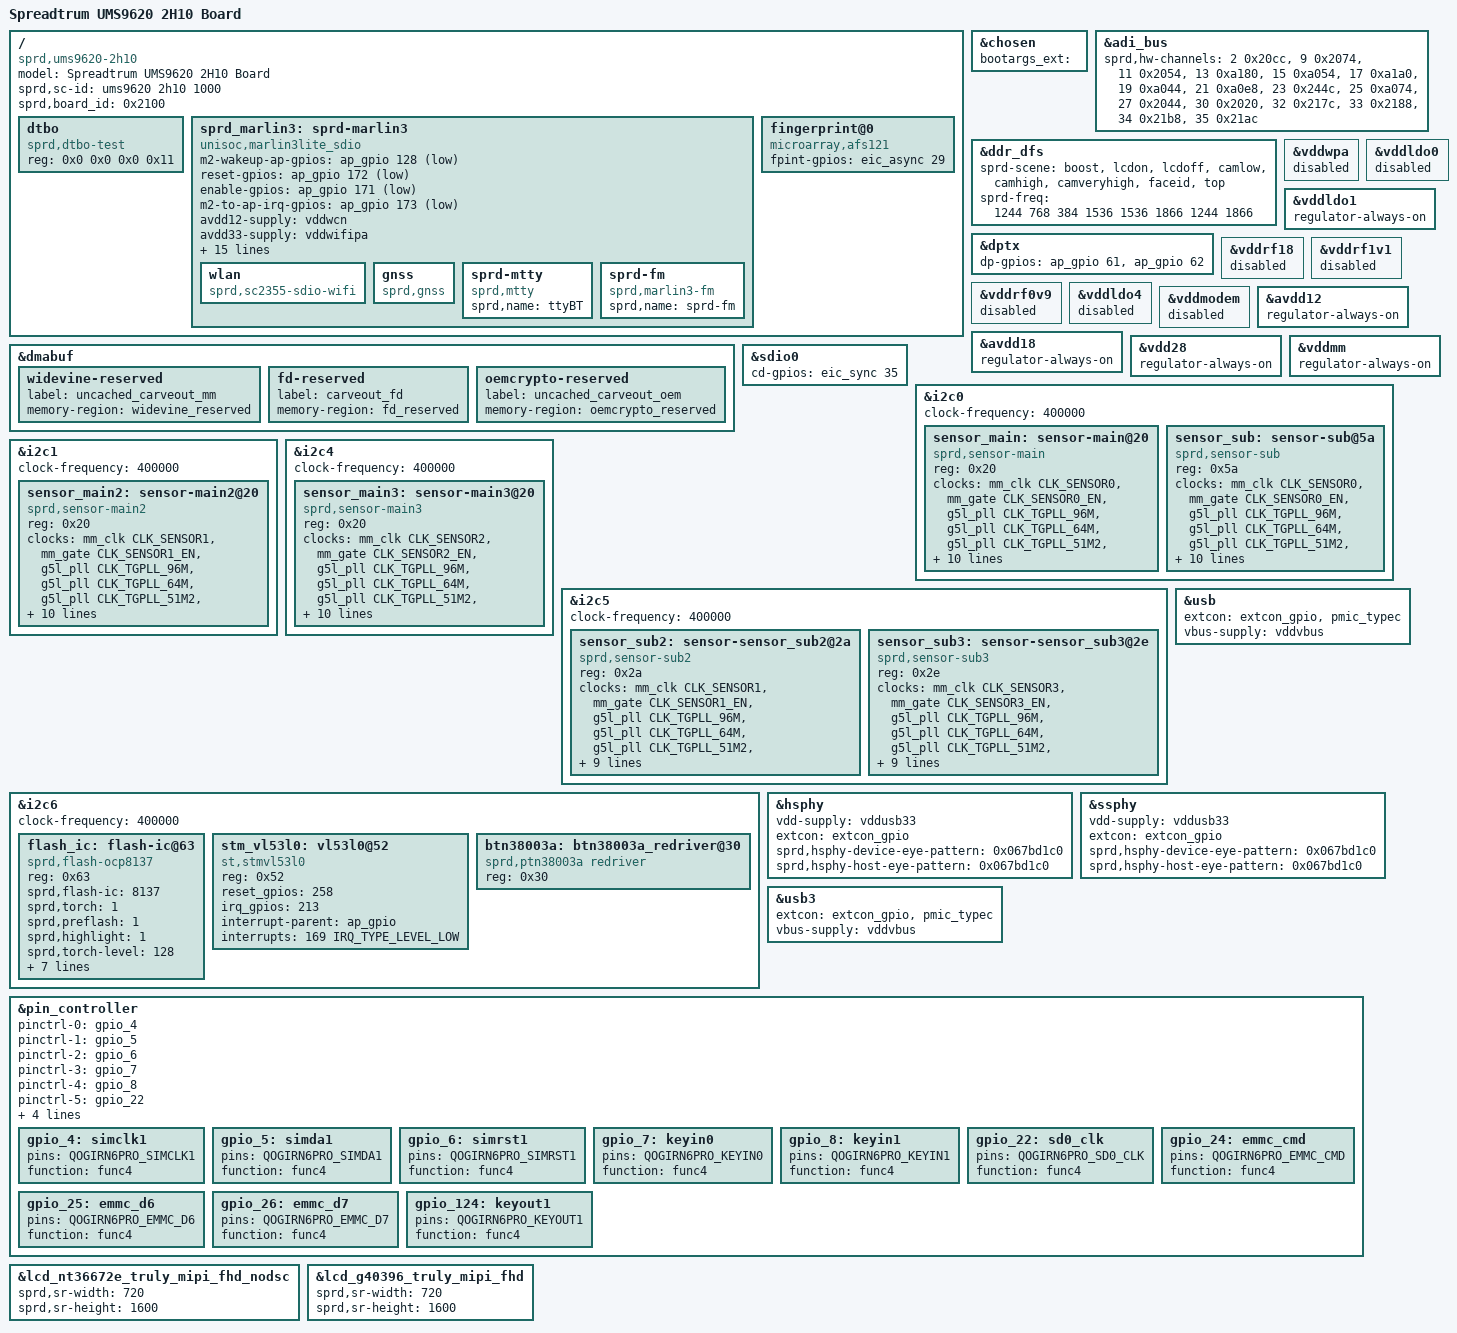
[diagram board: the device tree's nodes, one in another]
/dts-v1/;
/plugin/;
#include <dt-bindings/gpio/gpio.h>
#include <dt-bindings/interrupt-controller/arm-gic.h>
#include <dt-bindings/clock/sprd,ums9620-clk.h>
#include <dt-bindings/usb/pd.h>
#include "lcd/lcd_g40396_truly_mipi_fhd.dtsi"
#include "lcd/lcd_nt36672e_truly_mipi_fhd_nodsc.dtsi"
#include "lcd/lcd_dummy_mipi.dtsi"
#include "reserved-memory/ums9620-2h10-overlay.dtsi"
#include "touchscreen/ums9620-spi1-gpio13-14-tp.dtsi"
#include "battery/ums9620-2h10-overlay.dtsi"
#include <dt-bindings/mfd/sprd,ump9620-regs.h>
#include <dt-bindings/mfd/sprd,ump9620-mask.h>
#include <dt-bindings/input/input.h>
#include <dt-bindings/clock/sprd,ums9620-clk.h>

/ {

	model = "Spreadtrum UMS9620 2H10 Board";

	compatible = "sprd,ums9620-2h10", "sprd,ums9620";

	sprd,sc-id = "ums9620 2h10 1000";

	sprd,board_id = <0x2100>; //XX00:base board,XX00~XXFF:customize board

	fragment {
		target-path = "/";
		__overlay__ {
			#address-cells = <2>;
			#size-cells = <2>;

			dtbo: dtbo {
				compatible = "sprd,dtbo-test";
				reg = <0x0 0x0 0x0 0x11>;
			};
			sprd_marlin3: sprd-marlin3 {
				compatible = "unisoc,marlin3lite_sdio";
				m2-wakeup-ap-gpios = <&ap_gpio 128 GPIO_ACTIVE_LOW>;
				reset-gpios = <&ap_gpio 172 GPIO_ACTIVE_LOW>;
				enable-gpios = <&ap_gpio 171 GPIO_ACTIVE_LOW>;
				m2-to-ap-irq-gpios = <&ap_gpio 173 GPIO_ACTIVE_LOW>;
				/* xtal-26m-clk-type = "TCXO"; */
				avdd12-supply = <&vddwcn>;
				avdd33-supply = <&vddwifipa>;
				dcxo18-supply = <&vddsim2>;
				clock-names = "clk_32k","source","enable";
				clocks = <&aonapb_gate CLK_AUX0>,
					 <&ext_32k>,
					 <&aonapb_gate CLK_AUX0_EB>;
				extcon = <&sdio1>;
				sdhci-name = <&sdio1>;
				sprd,btwf-file-name = "/dev/block/by-name/wcnmodem";
				sprd,gnss-file-name = "/vendor/firmware/gnssmodem.bin";
				adma-tx;
				adma-rx;
				/*
				 * bound parameter:
				 * [0]:addr offset, [1]:mask, [2]:unboundval, [3]:boundval
				 */
				avdd12-bound-wbreq = <REG_ANA_LDO_XTL_EN10 MASK_ANA_LDO_VDDWCN_EXT_XTL3_EN 0x0 MASK_ANA_LDO_VDDWCN_EXT_XTL3_EN>;
				avdd33-bound-wbreq = <REG_ANA_LDO_XTL_EN11 MASK_ANA_LDO_VDDWIFIPA_EXT_XTL3_EN 0x0 MASK_ANA_LDO_VDDWIFIPA_EXT_XTL3_EN>;

				wlan {
					compatible = "sprd,sc2355-sdio-wifi";
				};

				gnss {
					compatible = "sprd,gnss";
				};

				sprd-mtty {
					compatible = "sprd,mtty";
					sprd,name = "ttyBT";
				};

				sprd-fm {
					compatible = "sprd,marlin3-fm";
					sprd,name = "sprd-fm";
				};

			};

			fingerprint@0 {
				compatible = "microarray,afs121";
				fpint-gpios = <&eic_async 29 0>;
  			};

		};
	};
};

&chosen {
	bootargs_ext = "";
};

&adi_bus {
	sprd,hw-channels = <2 0x20cc>, <9 0x2074>, <11 0x2054>, <13 0xa180>,
			<15 0xa054>, <17 0xa1a0>, <19 0xa044>, <21 0xa0e8>,
			<23 0x244c>, <25 0xa074>, <27 0x2044>, <30 0x2020>,
			<32 0x217c>, <33 0x2188>, <34 0x21b8>, <35 0x21ac>;
};

&ddr_dfs {
		sprd-scene = "boost", "lcdon", "lcdoff", "camlow",
			"camhigh", "camveryhigh", "faceid", "top";
		sprd-freq = <1244 768 384 1536 1536 1866 1244 1866>;
};

&dptx {
	dp-gpios = <&ap_gpio 61 GPIO_ACTIVE_HIGH>,
			<&ap_gpio 62 GPIO_ACTIVE_HIGH>;
};

&vddwpa {
	status = "disabled";
};

&vddldo0 {
	status = "disabled";
};

&vddldo1 {
	regulator-always-on;
};

&vddrf18 {
	status = "disabled";
};

&vddrf1v1 {
	status = "disabled";
};

&vddrf0v9 {
	status = "disabled";
};

&vddldo4 {
	status = "disabled";
};

&vddmodem {
	status = "disabled";
};

&avdd12 {
	regulator-always-on;
};

&avdd18 {
	regulator-always-on;
};

&vdd28 {
	regulator-always-on;
};

&vddmm {
	regulator-always-on;
};

&dmabuf {
	widevine-reserved {
		label = "uncached_carveout_mm";
		memory-region = <&widevine_reserved>;
	};

	fd-reserved {
		label = "carveout_fd";
		memory-region = <&fd_reserved>;
	};

	oemcrypto-reserved {
		label = "uncached_carveout_oem";
		memory-region = <&oemcrypto_reserved>;
	};
};

&sdio0 {
	cd-gpios = <&eic_sync 35 GPIO_ACTIVE_HIGH>;
};

&i2c0 {
	status = "okay";
	clock-frequency = <400000>;

	sensor_main: sensor-main@20 {
		compatible = "sprd,sensor-main";
		reg = <0x20>;
		clock-names = "clk_src","sensor_eb",
			"clk_96m","clk_64m",
			"clk_51m2","clk_48m","clk_26m";
		clocks = <&mm_clk CLK_SENSOR0>,<&mm_gate CLK_SENSOR0_EN>,
				<&g5l_pll CLK_TGPLL_96M>,<&g5l_pll CLK_TGPLL_64M>,
				<&g5l_pll CLK_TGPLL_51M2>,<&g5l_pll CLK_TGPLL_48M>,<&ext_26m>;
		vddio-supply = <&vddcamio>;
		vddcama-supply = <&vddcama0>;
		vddcamd-supply = <&vddcamd0>;
		vddcammot-supply = <&vddcammot0>;
		reset-gpios = <&ap_gpio 40 0>;
		power-down-gpios = <&ap_gpio 46 0>;
		sprd,phyid = <0>;
		csi = <&csi0>;
		power-domains = <&mm_domain>;
	};

	sensor_sub: sensor-sub@5a {
		compatible = "sprd,sensor-sub";
		reg = <0x5a>;
		clock-names = "clk_src","sensor_eb",
			"clk_96m","clk_64m",
			"clk_51m2","clk_48m","clk_26m";
		clocks = <&mm_clk CLK_SENSOR0>,<&mm_gate CLK_SENSOR0_EN>,
			<&g5l_pll CLK_TGPLL_96M>,<&g5l_pll CLK_TGPLL_64M>,
			<&g5l_pll CLK_TGPLL_51M2>,<&g5l_pll CLK_TGPLL_48M>,<&ext_26m>;
		vddio-supply = <&vddcamio>;
		vddcama-supply = <&vddcama0>;
		vddcamd-supply = <&vddcamd0>;
		vddcammot-supply = <&vddcammot0>;
		reset-gpios = <&ap_gpio 39 0>;
		power-down-gpios = <&ap_gpio 45 0>;
		sprd,phyid = <1>;
		csi = <&csi1>;
		power-domains = <&mm_domain>;
	};
};

&i2c1 {
	status = "okay";
	clock-frequency = <400000>;

	sensor_main2: sensor-main2@20 {
		compatible = "sprd,sensor-main2";
		reg = <0x20>;
		clock-names = "clk_src","sensor_eb",
			"clk_96m","clk_64m",
			"clk_51m2","clk_48m","clk_26m";
		clocks = <&mm_clk CLK_SENSOR1>,<&mm_gate CLK_SENSOR1_EN>,
			<&g5l_pll CLK_TGPLL_96M>,<&g5l_pll CLK_TGPLL_64M>,
			<&g5l_pll CLK_TGPLL_51M2>,<&g5l_pll CLK_TGPLL_48M>,<&ext_26m>;
		vddio-supply = <&vddcamio>;
		vddcama-supply = <&vddcama1>;
		avdd-gpios = <&ap_gpio 79 0>;
		vddcamd-supply = <&vddcamd1>;
		reset-gpios = <&ap_gpio 41 0>;
		power-down-gpios = <&ap_gpio 47 0>;
		sprd,phyid = <3>;/*6*/
		csi = <&csi3>;
		power-domains = <&mm_domain>;
	};
};

&i2c4 {
	status = "okay";
	clock-frequency = <400000>;

	sensor_main3: sensor-main3@20 {
		compatible = "sprd,sensor-main3";
		reg = <0x20>;
		clock-names = "clk_src","sensor_eb",
			"clk_96m","clk_64m",
			"clk_51m2","clk_48m","clk_26m";
		clocks = <&mm_clk CLK_SENSOR2>,<&mm_gate CLK_SENSOR2_EN>,
			<&g5l_pll CLK_TGPLL_96M>,<&g5l_pll CLK_TGPLL_64M>,
			<&g5l_pll CLK_TGPLL_51M2>,<&g5l_pll CLK_TGPLL_48M>,<&ext_26m>;
		vddio-supply = <&vddcamio>;
		vddcama-supply = <&vddcama2>;
		vddcamd-supply = <&vddcamd2>;
		vddcammot-supply = <&vddcammot1>;
		mot-gpios = <&ap_gpio 78 0>;
		reset-gpios = <&ap_gpio 42 0>;
		sprd,phyid = <2>;/*4*/
		csi = <&csi2>;
		power-domains = <&mm_domain>;
	};
};

&i2c5 {
	status = "okay";
	clock-frequency = <400000>;

	sensor_sub2: sensor-sensor_sub2@2a {
		compatible = "sprd,sensor-sub2";
		reg = <0x2a>;
		clock-names = "clk_src","sensor_eb",
			"clk_96m","clk_64m",
			"clk_51m2","clk_48m","clk_26m";
		clocks = <&mm_clk CLK_SENSOR1>,<&mm_gate CLK_SENSOR1_EN>,
			<&g5l_pll CLK_TGPLL_96M>,<&g5l_pll CLK_TGPLL_64M>,
			<&g5l_pll CLK_TGPLL_51M2>,<&g5l_pll CLK_TGPLL_48M>,<&ext_26m>;
		vddio-supply = <&vddcamio>;
		vddcama-supply = <&vddcama1>;
		vddcamd-supply = <&vddcamd1>;
		reset-gpios = <&ap_gpio 44 0>;
		power-down-gpios = <&ap_gpio 50 0>;
		sprd,phyid = <5>;
		csi = <&csi2>;
		power-domains = <&mm_domain>;
	};

	sensor_sub3: sensor-sensor_sub3@2e {
		compatible = "sprd,sensor-sub3";
		reg = <0x2e>;
		clock-names = "clk_src","sensor_eb",
			"clk_96m","clk_64m",
			"clk_51m2","clk_48m","clk_26m";
		clocks = <&mm_clk CLK_SENSOR3>,<&mm_gate CLK_SENSOR3_EN>,
			<&g5l_pll CLK_TGPLL_96M>,<&g5l_pll CLK_TGPLL_64M>,
			<&g5l_pll CLK_TGPLL_51M2>,<&g5l_pll CLK_TGPLL_48M>,<&ext_26m>;
		vddio-supply = <&vddcamio>;
		vddcama-supply = <&vddcama2>;
		vddcamd-supply = <&vddcamd2>;
		reset-gpios = <&ap_gpio 43 0>;
		power-down-gpios = <&ap_gpio 49 0>;
		sprd,phyid = <7>;
		csi = <&csi3>;
		power-domains = <&mm_domain>;
	};
};

&i2c6 {
	status = "okay";
	clock-frequency = <400000>;

	flash_ic: flash-ic@63 {
		compatible = "sprd,flash-ocp8137";
		reg = <0x63>;
		sprd,flash-ic = <8137>;
		sprd,torch = <1>;
		sprd,preflash = <1>;
		sprd,highlight = <1>;
		sprd,torch-level = <128>;
		sprd,preflash-level = <128>;
		sprd,highlight-level = <128>;
		sprd,lvfm-enable = <1>;
		flash-torch-en-gpios = <&ap_gpio 112 0>;
		flash-chip-en-gpios = <&ap_gpio 119 0>;
		flash-en-gpios = <&ap_gpio 111 0>;
		flash-sync-gpios = <&ap_gpio 59 0>;
	};

	stm_vl53l0: vl53l0@52 {
		compatible = "st,stmvl53l0";
		reg = <0x52>;
		reset_gpios = <258>;
		irq_gpios = <213>;
		interrupt-parent = <&ap_gpio>;
		interrupts = <169 IRQ_TYPE_LEVEL_LOW>;
	};

	btn38003a: btn38003a_redriver@30 {
		compatible = "sprd,ptn38003a redriver";
		reg = <0x30>;
	};
};

&hsphy {
	vdd-supply = <&vddusb33>;
	extcon = <&extcon_gpio>;
	sprd,hsphy-device-eye-pattern = <0x067bd1c0>;
	sprd,hsphy-host-eye-pattern = <0x067bd1c0>;
	status = "okay";
};

&usb {
	extcon = <&extcon_gpio>, <&pmic_typec>;
	vbus-supply = <&vddvbus>;
	status = "okay";
};

&ssphy {
	vdd-supply = <&vddusb33>;
	extcon = <&extcon_gpio>;
	sprd,hsphy-device-eye-pattern = <0x067bd1c0>;
	sprd,hsphy-host-eye-pattern = <0x067bd1c0>;
	status = "okay";
};

&usb3 {
	extcon = <&extcon_gpio>, <&pmic_typec>;
	vbus-supply = <&vddvbus>;
	status = "okay";
};

&pin_controller {
	pinctrl-names =
	/* IM1_CLK ,SIM1_DA ,SIM1_RST ,keyin0 */
	 "gpio_4", "gpio_5", "gpio_6", "gpio_7",
	/* keyin1 ,sd0_clk, emmc_cmd */
	"gpio_8", "gpio_22", "gpio_24",
	/* emmc_d6, emmc_d7, emmc_d7 */
	"gpio_25", "gpio_26", "gpio_124";

	pinctrl-0 = <&gpio_4>;
	pinctrl-1 = <&gpio_5>;
	pinctrl-2 = <&gpio_6>;
	pinctrl-3 = <&gpio_7>;
	pinctrl-4 = <&gpio_8>;
	pinctrl-5 = <&gpio_22>;
	pinctrl-6 = <&gpio_24>;
	pinctrl-7 = <&gpio_25>;
	pinctrl-8 = <&gpio_26>;
	pinctrl-9 = <&gpio_124>;

	gpio_4: simclk1 {
		pins = "QOGIRN6PRO_SIMCLK1";
		function = "func4";
	};

	gpio_5: simda1 {
		pins = "QOGIRN6PRO_SIMDA1";
		function = "func4";
	};

	gpio_6: simrst1 {
		pins = "QOGIRN6PRO_SIMRST1";
		function = "func4";
	};

	gpio_7: keyin0 {
		pins = "QOGIRN6PRO_KEYIN0";
		function = "func4";
	};

	gpio_8: keyin1 {
		pins = "QOGIRN6PRO_KEYIN1";
		function = "func4";
	};

	gpio_22: sd0_clk {
		pins = "QOGIRN6PRO_SD0_CLK";
		function = "func4";
	};

	gpio_24: emmc_cmd {
		pins = "QOGIRN6PRO_EMMC_CMD";
		function = "func4";
	};

	gpio_25: emmc_d6 {
		pins = "QOGIRN6PRO_EMMC_D6";
		function = "func4";
	};

	gpio_26: emmc_d7 {
		pins = "QOGIRN6PRO_EMMC_D7";
		function = "func4";
	};

	gpio_124: keyout1 {
		pins = "QOGIRN6PRO_KEYOUT1";
		function = "func4";
	};
};

&lcd_nt36672e_truly_mipi_fhd_nodsc {
	sprd,sr-width = <720>;
	sprd,sr-height = <1600>;
};

&lcd_g40396_truly_mipi_fhd {
	sprd,sr-width = <720>;
	sprd,sr-height = <1600>;
};
